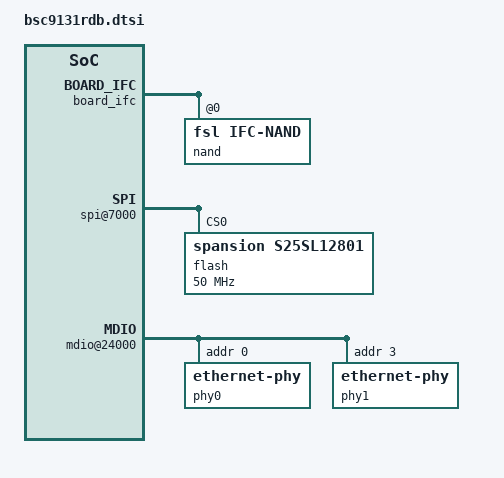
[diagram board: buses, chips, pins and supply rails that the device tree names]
&board_ifc {
	nand@0,0 {
		#address-cells = <1>;
		#size-cells = <1>;
		compatible = "fsl,ifc-nand";
		reg = <0x0 0x0 0x4000>;
	};
};
&board_soc {
	i2c@3100 {
		status = "disabled";
	};
	spi@7000 {
		flash@0 {
			#address-cells = <1>;
			#size-cells = <1>;
			compatible = "spansion,s25sl12801", "jedec,spi-nor";
			reg = <0>;
			spi-max-frequency = <50000000>;
		};
	};
	usb@22000 {
		phy_type = "ulpi";
	};
	mdio@24000 {
		phy0: ethernet-phy@0 {
			interrupts = <3 1 0 0>;
			reg = <0x0>;
		};
		phy1: ethernet-phy@1 {
			interrupts = <2 1 0 0>;
			reg = <0x3>;
		};
	};
	sdhc@2e000 {
		status = "disabled";
	};
	ptp_clock@b0e00 {
		compatible = "fsl,etsec-ptp";
		reg = <0xb0e00 0xb0>;
		interrupts = <68 2 0 0 69 2 0 0>;
		fsl,tclk-period	= <5>;
		fsl,tmr-prsc	= <2>;
		fsl,tmr-add	= <0xcccccccd>;
		fsl,tmr-fiper1	= <999999995>;
		fsl,tmr-fiper2	= <99990>;
		fsl,max-adj	= <249999999>;
	};
	enet0: ethernet@b0000 {
		phy-handle = <&phy0>;
		phy-connection-type = "rgmii-id";
	};
	enet1: ethernet@b1000 {
		phy-handle = <&phy1>;
		phy-connection-type = "rgmii-id";
	};
};
